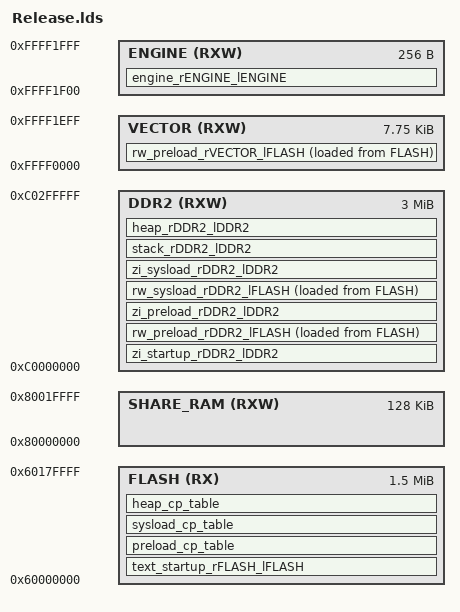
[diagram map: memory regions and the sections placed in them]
/* ld Linker Script - (Debug/Release) */
/* Auto generated by DJYOS lds Editor */
/* Mon Jun 17 16:03:21 CST 2013 */

MEMORY
{
	FLASH(RX)		: org = 0x60000000, len = 0x180000
	DDR2(RXW)		: org = 0xc0000000, len = 0x300000
	VECTOR(RXW)		: org = 0xffff0000, len = 8k-0x100
	ENGINE(RXW)		: org = 0xffff1f00, len = 0x100
	SHARE_RAM(RXW)		: org = 0x80000000, len = 128k
}

SECTIONS
{
	
	. = ALIGN(0x08);
	text_startup_rFLASH_lFLASH :
	{
		./src/OS_code/bsp/arch/omapl138/startup/initcpu.o (.text .text.* .rodata .rodata.*)
		./src/OS_code/bsp/arch/omapl138/startup/initcpuc.o (.text .text.* .rodata .rodata.*)
		./src/OS_code/bsp/arch/arm_common/exceptions.o (.text .text.* .rodata .rodata.*)
		./src/OS_code/bsp/arch/arm_common/mmu.o (.text .text.* .rodata .rodata.*)
		./src/OS_code/bsp/arch/arm_common/cache.o (.text .text.* .rodata .rodata.*)
		./src/OS_code/loader/si/pre_loader.o (.text .text.* .rodata .rodata.*)
	}>FLASH 
	
	. = ALIGN(0x08);
	zi_startup_rDDR2_lDDR2 (NOLOAD) :
	{
		./src/OS_code/bsp/arch/arm_common/mmucache.o (.mmutable)
	}>DDR2 
	
	. = ALIGN(0x08);
	rw_preload_rVECTOR_lFLASH :
	{
		KEEP(* (.isr_vector .isr_vector.*))
	}>VECTOR AT>FLASH
	
	. = ALIGN(0x08);
	rw_preload_rDDR2_lFLASH :
	{
		./src/OS_code/loader/si/loader.o (.text .text.* .rodata .rodata.*)
		./src/OS_code/bsp/arch/omapl138/core/int_hard.o (.text .text.* .rodata .rodata.*)
		./src/OS_code/djyos/int/int.o (.text .text.* .rodata .rodata.*)
		./src/OS_code/bsp/arch/omapl138/core/ints.o (.text .text.* .rodata .rodata.*)
		./src/user/critical/*.o (.text .text.* .rodata .rodata.*)
		./src/OS_code/bsp/cpu_peripheral/src/*.o (.text .text.* .rodata .rodata.*)
		./src/OS_code/bsp/board_peripheral/lcd/*.o (.text .text.* .rodata .rodata.*)
		./src/OS_code/loader/si/loader.o (.data .data.*)
		./src/OS_code/bsp/arch/omapl138/core/int_hard.o (.data .data.*)
		./src/OS_code/djyos/int/int.o (.data .data.*)
		./src/OS_code/bsp/arch/omapl138/core/ints.o (.data .data.*)
		./src/user/critical/*.o (.data .data.*)
		./src/OS_code/bsp/cpu_peripheral/src/*.o (.data .data.*)
		./src/OS_code/bsp/board_peripheral/lcd/*.o (.data .data.*)
	}>DDR2 AT>FLASH
	
	. = ALIGN(0x08);
	zi_preload_rDDR2_lDDR2 (NOLOAD) :
	{
		./src/OS_code/loader/si/loader.o (.bss .bss.* COMMON)
		./src/OS_code/bsp/arch/omapl138/core/int_hard.o (.bss .bss.* COMMON)
		./src/OS_code/djyos/int/int.o (.bss .bss.* COMMON)
		./src/OS_code/bsp/arch/omapl138/core/ints.o (.bss .bss.* COMMON)
		./src/user/critical/*.o (.bss .bss.* COMMON)
		./src/OS_code/bsp/cpu_peripheral/src/*.o (.bss .bss.* COMMON)
		./src/OS_code/bsp/board_peripheral/lcd/*.o (.bss .bss.* COMMON)
	}>DDR2 
	
	. = ALIGN(0x08);
	rw_sysload_rDDR2_lFLASH :
	{
		* (.text .text.* .rodata .rodata.*)
		* (.data .data.*)
	}>DDR2 AT>FLASH
	
	. = ALIGN(0x08);
	zi_sysload_rDDR2_lDDR2 (NOLOAD) :
	{
		* (.bss .bss.* COMMON)
	}>DDR2 
	
	. = ALIGN(0x08);
	preload_cp_table :
	{
		preload_copy_table = .;
		LONG(16)
		LONG(3)
		
		LONG(LOADADDR(rw_preload_rVECTOR_lFLASH))
		LONG(ADDR(rw_preload_rVECTOR_lFLASH))
		LONG(SIZEOF(rw_preload_rVECTOR_lFLASH))
		LONG(1)
		
		LONG(LOADADDR(rw_preload_rDDR2_lFLASH))
		LONG(ADDR(rw_preload_rDDR2_lFLASH))
		LONG(SIZEOF(rw_preload_rDDR2_lFLASH))
		LONG(1)
		
		LONG(LOADADDR(zi_preload_rDDR2_lDDR2))
		LONG(ADDR(zi_preload_rDDR2_lDDR2))
		LONG(SIZEOF(zi_preload_rDDR2_lDDR2))
		LONG(0)
	}>FLASH 
	
	. = ALIGN(0x08);
	sysload_cp_table :
	{
		sysload_copy_table = .;
		LONG(16)
		LONG(2)
		
		LONG(LOADADDR(rw_sysload_rDDR2_lFLASH))
		LONG(ADDR(rw_sysload_rDDR2_lFLASH))
		LONG(SIZEOF(rw_sysload_rDDR2_lFLASH))
		LONG(1)
		
		LONG(LOADADDR(zi_sysload_rDDR2_lDDR2))
		LONG(ADDR(zi_sysload_rDDR2_lDDR2))
		LONG(SIZEOF(zi_sysload_rDDR2_lDDR2))
		LONG(0)
	}>FLASH 
	
	. = ALIGN(0x08);
	stack_rDDR2_lDDR2 (NOLOAD) :
	{
		usr_bottom = .;
		KEEP(* (.stack.usr .stack.usr.*))
		usr_top = ALIGN(0x08);
		
		svc_bottom = .;
		KEEP(* (.stack.svc .stack.svc.*))
		svc_top = ALIGN(0x08);
		
		irq_bottom = .;
		KEEP(* (.stack.irq .stack.irq.*))
		irq_top = ALIGN(0x08);
		
		fiq_bottom = .;
		KEEP(* (.stack.fiq .stack.fiq.*))
		fiq_top = ALIGN(0x08);
		
		undef_bottom = .;
		KEEP(* (.stack.undef .stack.undef.*))
		undef_top = ALIGN(0x08);
		
		abort_bottom = .;
		KEEP(* (.stack.abort .stack.abort.*))
		abort_top = ALIGN(0x08);
		
	}>DDR2 
	
	. = ALIGN(0x08);
	heap_rDDR2_lDDR2 (NOLOAD) :
	{
		sys_heap_bottom = .;
	}>DDR2 
	sys_heap_top = 0xc0000000+0x300000;
	
	. = ALIGN(0x08);
	heap_cp_table :
	{
		heap_copy_table = .;
		LONG(12)
		LONG(1)
		
		sys_heap_bottom_cnt = .;
		LONG(sys_heap_bottom)
		sys_heap_top_cnt = .;
		LONG(sys_heap_top)
	}>FLASH 
	
	. = ALIGN(0x08);
	engine_rENGINE_lENGINE (NOLOAD) :
	{
		engine_irq = .;
		. += 0x04;
		engine_fiq = .;
		. += 0x04;
		engine_undef = .;
		. += 0x04;
		engine_swi = .;
		. += 0x04;
		engine_pabort = .;
		. += 0x04;
		engine_dabort = .;
		. += 0x04;
		engine_reserved = .;
		. += 0x04;
	}>ENGINE 
}
/**** The End ****/
